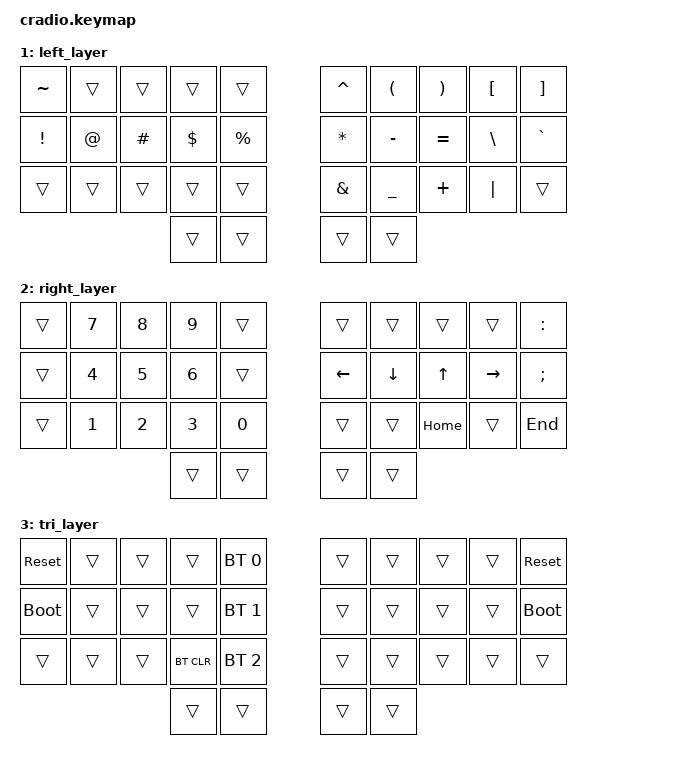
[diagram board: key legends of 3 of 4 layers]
// Copyright (c) 2022 The ZMK Contributors
// SPDX-License-Identifier: MIT

#include <behaviors.dtsi>
#include <dt-bindings/zmk/keys.h>
#include <dt-bindings/zmk/bt.h>
#include "cradio_labels.h"

// Home row mods macro
#define HRML(k1,k2,k3,k4) &ht LCTRL k1  &ht LALT  k2  &ht LALT  k3  &ht LGUI  k4
#define HRMR(k1,k2,k3,k4) &ht RGUI  k1  &ht RALT  k2  &ht RALT  k3  &ht RCTRL k4

#define LEFTTHUMB &thumb LGUI SPACE

&lt {
    flavor = "hold-preferred";
    quick-tap-ms = <175>;
};

/ {
    combos {
        compatible = "zmk,combos";
        combo_esc {
            timeout-ms = <50>;
            key-positions = <RM1 RM2>;
            bindings = <&kp ESC>;
        };
        combo_cmd_space {
            timeout-ms = <50>;
            key-positions = <RB1 RB2>;
            bindings = <&kp LG(SPACE)>;
        };
        combo_colon {
            timeout-ms = <50>;
            key-positions = <RB3 RB4>;
            bindings = <&kp COLON>;
        };
        combo_open_curly_brace {
            timeout-ms = <50>;
            key-positions = <RT2 RT3>;
            bindings = <&kp LBRC>;
            require-prior-idle-ms = <150>;
        };
        combo_close_curly_brace {
            timeout-ms = <50>;
            key-positions = <RT3 RT4>;
            bindings = <&kp RBRC>;
            require-prior-idle-ms = <150>;
        };
        combo_tilde {
            timeout-ms = <50>;
            key-positions = <LT4 LT3>;
            bindings = <&kp TILDE>;
        };
    };

    behaviors {
        ht: hold_tap {
            compatible = "zmk,behavior-hold-tap";
            #binding-cells = <2>;
            flavor = "balanced";
            tapping-term-ms = <175>;
            quick-tap-ms = <150>;
            require-prior-idle-ms = <100>;
            bindings = <&kp>, <&kp>;
        };

        thumb: thumb_hold_tap {
            compatible = "zmk,behavior-hold-tap";
            #binding-cells = <2>;
            flavor = "balanced";
            tapping-term-ms = <200>;
            quick-tap-ms = <175>;
            bindings = <&kp>, <&kp>;
        };
    };

    conditional_layers {
        compatible = "zmk,conditional-layers";
        tri_layer {
            if-layers = <1 2>;
            then-layer = <3>;
        };
    };

    keymap {
        compatible = "zmk,keymap";
        default_layer {
            bindings = <
        //╭──────────┬──────────┬──────────┬──────────┬──────────╮   ╭──────────┬──────────┬──────────┬──────────┬──────────╮
        //│  Q       │  W       │  E       │  R       │  T       │   │  Y       │  U       │  I       │  O       │  P       │
            &kp Q      &kp W      &kp E      &kp R      &kp T          &kp Y      &kp U      &kp I      &kp O      &kp P
        //├──────────┼──────────┼──────────┼──────────┼──────────┤   ├──────────┼──────────┼──────────┼──────────┼──────────┤
        //│  A       │  S       │  D       │  F       │  G       │   │  H       │  J       │  K       │  L       │ ' "      │
            HRML(A,     S,         D,         F)         &kp G          &kp H      HRMR(J,    K,         L,        SQT)
        //├──────────┼──────────┼──────────┼──────────┼──────────┤   ├──────────┼──────────┼──────────┼──────────┼──────────┤
        //│  Z       │  X       │  C       │  V       │  B       │   │  N       │  M       │ , <      │ . >      │ / ?      │
           &mt LSHFT Z  &kp X      &kp C      &kp V      &kp B          &kp N      &kp M     &kp COMMA  &kp DOT    &mt RSHFT FSLH
        //╰──────────┴──────────┴──────────┼──────────┼──────────┤   ├──────────┼──────────┼──────────┴──────────┴──────────╯
                                            &lt 2 TAB   LEFTTHUMB     &kp ENTER  &lt 1 BSPC
        //                                 ╰──────────┴──────────╯   ╰──────────┴──────────╯
            >;
        };

        left_layer {
            bindings = <
        //╭──────────┬──────────┬──────────┬──────────┬──────────╮   ╭──────────┬──────────┬──────────┬──────────┬──────────╮
        //│  ~       │          │          │          │          │   │  ^       │  (       │  )       │  [       │  ]       │
            &kp TILDE  &trans      &trans     &trans    &trans         &kp CARET  &kp LPAR   &kp RPAR   &kp LBKT   &kp RBKT
        //├──────────┼──────────┼──────────┼──────────┼──────────┤   ├──────────┼──────────┼──────────┼──────────┼──────────┤
        //│  !       │  @       │  #       │  $       │  %       │   │  *       │  -       │  =       │  \       │  `       │
            &kp EXCL   &kp AT     &kp HASH   &kp DLLR   &kp PRCNT      &kp ASTRK  &kp MINUS  &kp EQUAL  &kp BSLH   &kp GRAVE
        //├──────────┼──────────┼──────────┼──────────┼──────────┤   ├──────────┼──────────┼──────────┼──────────┼──────────┤
        //│          │          │          │          │          │   │  &       │  _       │  +       │  │       │          │
            &trans     &trans     &trans     &trans     &trans         &kp AMPS   &kp UNDER  &kp PLUS   &kp PIPE   &trans
        //╰──────────┴──────────┴──────────┼──────────┼──────────┤   ├──────────┼──────────┼──────────┴──────────┴──────────╯
                                             &trans     &trans         &trans     &trans
        //                                 ╰──────────┴──────────╯   ╰──────────┴──────────╯
            >;
        };

        right_layer {
            bindings = <
        //╭──────────┬──────────┬──────────┬──────────┬──────────╮   ╭──────────┬──────────┬──────────┬──────────┬──────────╮
        //│          │  7       │  8       │  9       │          │   │          │          │          │          │  :       │
            &trans     &kp N7     &kp N8     &kp N9     &trans         &trans     &trans     &trans     &trans     &kp COLON
        //├──────────┼──────────┼──────────┼──────────┼──────────┤   ├──────────┼──────────┼──────────┼──────────┼──────────┤
        //│          │  4       │  5       │  6       │          │   │ LEFT     │ DOWN     │ UP       │ RIGHT    │  ;       │
            &trans     &kp N4     &kp N5     &kp N6     &trans         &kp LEFT   &kp DOWN   &kp UP   &kp RIGHT   &kp SEMI
        //├──────────┼──────────┼──────────┼──────────┼──────────┤   ├──────────┼──────────┼──────────┼──────────┼──────────┤
        //│          │  1       │  2       │  3       │  0       │   │          │          │  HOME    │          │ END      │
            &trans     &kp N1     &kp N2     &kp N3     &kp N0         &trans     &trans     &kp HOME   &trans     &kp END
        //╰──────────┴──────────┴──────────┼──────────┼──────────┤   ├──────────┼──────────┼──────────┴──────────┴──────────╯
                                             &trans     &trans         &trans     &trans
        //                                 ╰──────────┴──────────╯   ╰──────────┴──────────╯
            >;
        };

        tri_layer {
            bindings = <
        //╭──────────┬──────────┬──────────┬──────────┬──────────╮   ╭──────────┬──────────┬──────────┬──────────┬──────────╮
        //│ RESET    │          │          │          │PROFILE 0 │   │          │          │          │          │  RESET   │
           &sys_reset  &trans     &trans     &trans    &bt BT_SEL 0    &trans     &trans     &trans     &trans    &sys_reset
        //├──────────┼──────────┼──────────┼──────────┼──────────┤   ├──────────┼──────────┼──────────┼──────────┼──────────┤
        //│BOOTLOADER│          │          │          │PROFILE 1 │   │          │          │          │          │BOOTLOADER│
          &bootloader  &trans     &trans     &trans    &bt BT_SEL 1    &trans     &trans     &trans     &trans    &bootloader
        //├──────────┼──────────┼──────────┼──────────┼──────────┤   ├──────────┼──────────┼──────────┼──────────┼──────────┤
        //│          │          │          │ CLEAR BT │PROFILE 2 │   │          │          │          │          │          │
            &trans     &trans     &trans    &bt BT_CLR &bt BT_SEL 2    &trans     &trans     &trans     &trans     &trans
        //╰──────────┴──────────┴──────────┼──────────┼──────────┤   ├──────────┼──────────┼──────────┴──────────┴──────────╯
                                             &trans     &trans         &trans     &trans
        //                                 ╰──────────┴──────────╯   ╰──────────┴──────────╯
            >;
        };
    };
};
